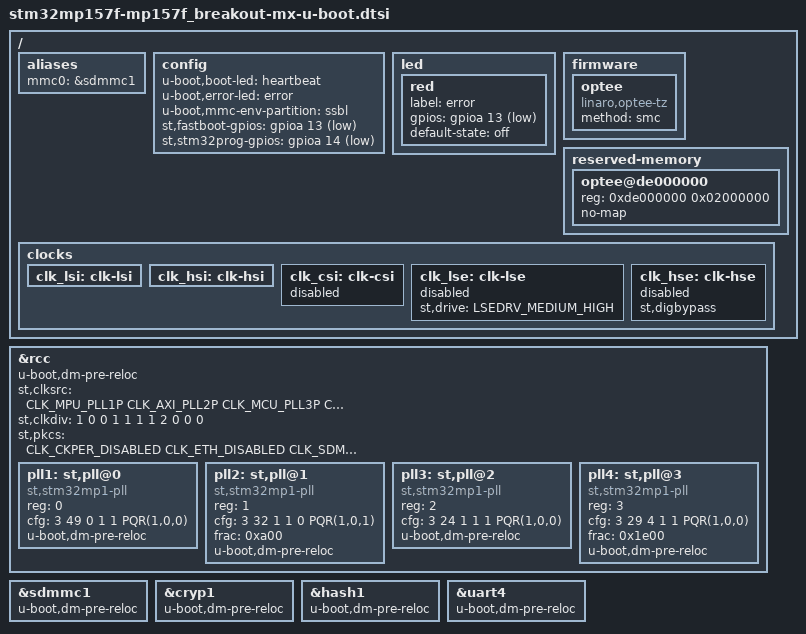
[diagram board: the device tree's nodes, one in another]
/* SPDX-License-Identifier: GPL-2.0+ OR BSD-3-Clause*/
/*
 * Copyright (C) 2021, STMicroelectronics - All Rights Reserved
 * Author: STM32CubeMX code generation for STMicroelectronics.
 */

/* For more information on Device Tree configuration, please refer to
 * https://wiki.st.com/stm32mpu/wiki/Category:Device_tree_configuration
 */

#include <dt-bindings/clock/stm32mp1-clksrc.h>
#include "stm32mp15-mx.dtsi"

#include "stm32mp15-u-boot.dtsi"
#include "stm32mp15-ddr.dtsi"

/* USER CODE BEGIN includes */

/* USER CODE END includes */

/ {

	/* USER CODE BEGIN root */
	aliases{
		//i2c3 = &i2c4;
		mmc0 = &sdmmc1;
		//usb0 = &usbotg_hs;
	};

	config{
		u-boot,boot-led = "heartbeat";
		u-boot,error-led = "error";
		u-boot,mmc-env-partition = "ssbl";
		//st,adc_usb_pd = <&adc1 18>, <&adc1 19>;
		st,fastboot-gpios = <&gpioa 13 GPIO_ACTIVE_LOW>;
		st,stm32prog-gpios = <&gpioa 14 GPIO_ACTIVE_LOW>;
	};

	led{

		red{
			label = "error";
			gpios = <&gpioa 13 GPIO_ACTIVE_LOW>;
			default-state = "off";
			status = "okay";
		};
	};

	firmware{

		optee{
			compatible = "linaro,optee-tz";
			method = "smc";
		};
	};

	reserved-memory{

		optee@de000000{
			reg = <0xde000000 0x02000000>;
			no-map;
		};
	};
	/* USER CODE END root */

	clocks {
		/* USER CODE BEGIN clocks */
		/* USER CODE END clocks */

#ifndef CONFIG_STM32MP1_TRUSTED
		clk_lsi: clk-lsi {

			/* USER CODE BEGIN clk_lsi */
			/* USER CODE END clk_lsi */
		};
		clk_hsi: clk-hsi {

			/* USER CODE BEGIN clk_hsi */
			/* USER CODE END clk_hsi */
		};
		clk_csi: clk-csi {
			status = "disabled";

			/* USER CODE BEGIN clk_csi */
			/* USER CODE END clk_csi */
		};
		clk_lse: clk-lse {
			status = "disabled";

			/* USER CODE BEGIN clk_lse */
			st,drive = < LSEDRV_MEDIUM_HIGH >;
			/* USER CODE END clk_lse */
		};
		clk_hse: clk-hse {
			status = "disabled";

			/* USER CODE BEGIN clk_hse */
			st,digbypass;
			/* USER CODE END clk_hse */
		};
#endif	/*CONFIG_STM32MP1_TRUSTED*/
	};

}; /*root*/

#ifndef CONFIG_STM32MP1_TRUSTED

&rcc {
	u-boot,dm-pre-reloc;
	st,clksrc = <
		CLK_MPU_PLL1P
		CLK_AXI_PLL2P
		CLK_MCU_PLL3P
		CLK_PLL12_HSI
		CLK_PLL3_HSI
		CLK_PLL4_HSI
		CLK_RTC_LSI
		CLK_MCO1_DISABLED
		CLK_MCO2_DISABLED
	>;
	st,clkdiv = <
		1 		/*MPU*/
		0 		/*AXI*/
		0 		/*MCU*/
		1 		/*APB1*/
		1 		/*APB2*/
		1 		/*APB3*/
		1 		/*APB4*/
		2 		/*APB5*/
		0 		/*RTC*/
		0 		/*MCO1*/
		0 		/*MCO2*/
	>;
	st,pkcs = <
		CLK_CKPER_DISABLED
		CLK_ETH_DISABLED
		CLK_SDMMC12_PLL4P
		CLK_STGEN_HSI
		CLK_USBPHY_DISABLED
		CLK_SPI2S1_DISABLED
		CLK_SPI2S23_DISABLED
		CLK_SPI45_DISABLED
		CLK_SPI6_DISABLED
		CLK_I2C46_DISABLED
		CLK_SDMMC3_DISABLED
		CLK_ADC_DISABLED
		CLK_CEC_DISABLED
		CLK_I2C12_DISABLED
		CLK_I2C35_DISABLED
		CLK_UART1_DISABLED
		CLK_UART24_HSI
		CLK_UART35_DISABLED
		CLK_UART6_DISABLED
		CLK_UART78_DISABLED
		CLK_SPDIF_DISABLED
		CLK_SAI1_DISABLED
		CLK_SAI2_DISABLED
		CLK_SAI3_DISABLED
		CLK_SAI4_DISABLED
		CLK_LPTIM1_DISABLED
		CLK_LPTIM23_DISABLED
		CLK_LPTIM45_DISABLED
	>;
	pll1:st,pll@0 {
		compatible = "st,stm32mp1-pll";
		reg = <0>;
		cfg = < 3 49 0 1 1 PQR(1,0,0) >;
		u-boot,dm-pre-reloc;
	};
	pll2:st,pll@1 {
		compatible = "st,stm32mp1-pll";
		reg = <1>;
		cfg = < 3 32 1 1 0 PQR(1,0,1) >;
		frac = < 0xa00 >;
		u-boot,dm-pre-reloc;
	};
	pll3:st,pll@2 {
		compatible = "st,stm32mp1-pll";
		reg = <2>;
		cfg = < 3 24 1 1 1 PQR(1,0,0) >;
		u-boot,dm-pre-reloc;
	};
	pll4:st,pll@3 {
		compatible = "st,stm32mp1-pll";
		reg = <3>;
		cfg = < 3 29 4 1 1 PQR(1,0,0) >;
		frac = < 0x1e00 >;
		u-boot,dm-pre-reloc;
	};
};

&sdmmc1{
	u-boot,dm-pre-reloc;

	/* USER CODE BEGIN sdmmc1 */
	/* USER CODE END sdmmc1 */
};

#endif	/*CONFIG_STM32MP1_TRUSTED*/

&cryp1{
	u-boot,dm-pre-reloc;

	/* USER CODE BEGIN cryp1 */
	/* USER CODE END cryp1 */
};

&hash1{
	u-boot,dm-pre-reloc;

	/* USER CODE BEGIN hash1 */
	/* USER CODE END hash1 */
};

&uart4{
	u-boot,dm-pre-reloc;

	/* USER CODE BEGIN uart4 */
	/* USER CODE END uart4 */
};

/* USER CODE BEGIN addons */
/* USER CODE END addons */

